# htmr_reva_me14 register map
Registers are access not given, no defined reset value unless marked. A register's access mark holds for its fields unless they carry their own. Offsets are from the block's base; lines under a group give offsets from that group; [hi:lo] are bit positions; {n}, {i} and the like mark numbered series; 'fields as' and 'values as' point back to an identical list; <NAME> marks a mode.

## Memory map
0x4001B000 HTMR size 0xFFF — High Speed Timer Module.

## Interrupts
93 HTimer (HTMR) — HTimer interrupt.

## HTMR — High Speed Timer Module.
Base 0x4001B000
0x00 SEC — HTimer Long-Interval Counter. This register contains the 32 most significant bits of the counter.
  [30:0] RTS — HTimer Long Interval Counter.
0x04 SSEC — HTimer Short Interval Counter. This counter ticks ever t_htclk (16.48uS). HTIMER_SEC is incremented when this register rolls over from 0xFF to 0x00.
  [7:0] RTSS — HTimer Short Interval Counter.
0x08 RAS — Long Interval Alarm.
  [19:0] RAS — HTimer Long Interval Alarm. An Alarm is triggered when this value matches HTIMER_SEC[19:0]
0x0C RSSA — HTimer Short Interval Alarm. This register contains the reload value for the short interval alarm, HTIMER_CTRL.alarm_ss_fl is raised on rollover.
  [31:0] RSSA — This register contains the reload value for the short interval alarm.
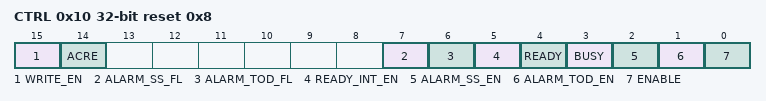
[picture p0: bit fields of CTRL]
0x10 CTRL reset 0x8 — HTimer Control Register.
  [15] WRITE_EN — Write Enable. This register bit serves as a protection mechanism against unintentional writes to critical HTimer bits.
    0=dis (Not active); 1=en (Active)
  [14] ACRE ro — Asynchronous Counter Read Enable, allows direct read access to sec and ssec counters regardless of the ready flag.
    0=disabled (Not allowed); 1=enabled (Allowed)
  [7] ALARM_SS_FL ro — Short Interval Alarm Interrupt Flag. This alarm is qualified as wake-up source to the processor.
    0=inactive (Not active); 1=Pending (Active)
  [6] ALARM_TOD_FL ro — Long Interval Alarm Interrupt Flag. This alarm is qualified as wake-up source to the processor.
    0=inactive (Not active); 1=pending (Active)
  [5] READY_INT_EN — HTimer Ready Interrupt Enable.
    0=dis (Disable.); 1=en (Enable.)
  [4] READY — HTimer Ready. This bit is set to 1 by hardware when the HTimer count registers update. It can be cleared to 0 by software at any time. It will also be cleared to 0 by hardware just prior to an update of the HTimer count register.
    0=busy (Register has not updated.); 1=ready
  [3] BUSY ro — HTimer Busy. This bit is set to 1 by hardware when changes to HTimer registers required a synchronized version of the register to be in place. This bit is automatically cleared by hardware.
    0=idle; 1=busy
  [2] ALARM_SS_EN — Short Interval Alarm Interrupt Enable. Change to this bit is effective only after BUSY is cleared from 1 to 0.
    0=dis (Disable.); 1=en (Enable.)
  [1] ALARM_TOD_EN — Long Interval Alarm Interrupt Enable. Change to this bit is effective only after BUSY is cleared from 1 to 0.
    0=dis (Disable.); 1=en (Enable.)
  [0] ENABLE — HTimer Enable. This bit enables the Real Time Clock. This bit can only be written when WE=1 and BUSY =0. Change to this bit is effective only after BUSY is cleared from 1 to 0.
    0=dis (Disable.); 1=en (Enable.)
